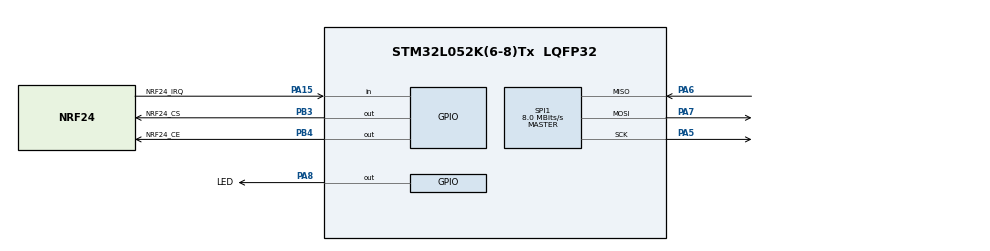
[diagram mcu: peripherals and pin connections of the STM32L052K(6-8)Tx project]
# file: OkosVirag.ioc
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ADC.EnableAnalogWatchDog=false
ADC.LowPowerAutoPowerOff=ENABLE
IWDG.Prescaler=IWDG_PRESCALER_256
Mcu.Family=STM32L0
Mcu.Name=STM32L052K(6-8)Tx
Mcu.Package=LQFP32
NVIC.RTC_IRQn=true\:0\:0\:false\:false\:true\:true
PA13.Mode=Serial_Wire
PA13.Signal=SYS_SWDIO
PA14.Mode=Serial_Wire
PA14.Signal=SYS_SWCLK
PA15.GPIO_Label=NRF24_IRQ
PA15.GPIO_PuPd=GPIO_PULLUP
PA15.Signal=GPIO_Input
PA5.Mode=Full_Duplex_Master
PA5.Signal=SPI1_SCK
PA6.Mode=Full_Duplex_Master
PA6.Signal=SPI1_MISO
PA7.Mode=Full_Duplex_Master
PA7.Signal=SPI1_MOSI
PA8.GPIO_Label=LED
PA8.Signal=GPIO_Output
PB3.GPIO_Label=NRF24_CS
PB3.GPIO_PuPd=GPIO_PULLUP
PB3.GPIO_Speed=GPIO_SPEED_FREQ_VERY_HIGH
PB3.Signal=GPIO_Output
PB4.GPIO_Label=NRF24_CE
PB4.GPIO_PuPd=GPIO_PULLUP
PB4.GPIO_Speed=GPIO_SPEED_FREQ_VERY_HIGH
PB4.Signal=GPIO_Output
ProjectManager.HeapSize=0x200
ProjectManager.StackSize=0x400
ProjectManager.TargetToolchain=SW4STM32
RCC.AHBFreq_Value=32000000
RCC.APB1Freq_Value=32000000
RCC.APB1TimFreq_Value=32000000
RCC.APB2Freq_Value=32000000
RCC.APB2TimFreq_Value=32000000
RCC.HCLKFreq_Value=32000000
RCC.HSI16_VALUE=16000000
RCC.HSI48_VALUE=48000000
RCC.HSI_VALUE=16000000
RCC.LSE_VALUE=32768
RCC.MSIClockRange=RCC_MSIRANGE_2
RCC.MSI_VALUE=262144
RCC.PLLMUL=RCC_PLLMUL_4
RCC.SYSCLKFreq_VALUE=32000000
RCC.SYSCLKSource=RCC_SYSCLKSOURCE_PLLCLK
RCC.VCOOutputFreq_Value=64000000
RTC.Format=RTC_FORMAT_BIN
RTC.WakeUpClock=RTC_WAKEUPCLOCK_CK_SPRE_16BITS
SPI1.BaudRatePrescaler=SPI_BAUDRATEPRESCALER_4
SPI1.CalculateBaudRate=8.0 MBits/s
SPI1.Direction=SPI_DIRECTION_2LINES
SPI1.Mode=SPI_MODE_MASTER
SPI1.VirtualType=VM_MASTER
VP_ADC_Vref_Input.Mode=IN-Vrefint
VP_IWDG_VS_IWDG.Mode=IWDG_Activate
VP_RTC_VS_RTC_Activate.Mode=RTC_Enabled
VP_RTC_VS_RTC_Calendar.Mode=RTC_Calendar
VP_RTC_VS_RTC_WakeUp_intern.Mode=WakeUp
board=OkosVirag

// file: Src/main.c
/**
  ******************************************************************************
  * File Name          : main.c
  * Description        : Main program body
  ******************************************************************************
  ** This notice applies to any and all portions of this file
  * that are not between comment pairs USER CODE BEGIN and
  * USER CODE END. Other portions of this file, whether
  * inserted by the user or by software development tools
  * are owned by their respective copyright owners.
  *
  * COPYRIGHT(c) 2018 STMicroelectronics
  *
  * Redistribution and use in source and binary forms, with or without modification,
  * are permitted provided that the following conditions are met:
  *   1. Redistributions of source code must retain the above copyright notice,
  *      this list of conditions and the following disclaimer.
  *   2. Redistributions in binary form must reproduce the above copyright notice,
  *      this list of conditions and the following disclaimer in the documentation
  *      and/or other materials provided with the distribution.
  *   3. Neither the name of STMicroelectronics nor the names of its contributors
  *      may be used to endorse or promote products derived from this software
  *      without specific prior written permission.
  *
  * THIS SOFTWARE IS PROVIDED BY THE COPYRIGHT HOLDERS AND CONTRIBUTORS "AS IS"
  * AND ANY EXPRESS OR IMPLIED WARRANTIES, INCLUDING, BUT NOT LIMITED TO, THE
  * IMPLIED WARRANTIES OF MERCHANTABILITY AND FITNESS FOR A PARTICULAR PURPOSE ARE
  * DISCLAIMED. IN NO EVENT SHALL THE COPYRIGHT HOLDER OR CONTRIBUTORS BE LIABLE
  * FOR ANY DIRECT, INDIRECT, INCIDENTAL, SPECIAL, EXEMPLARY, OR CONSEQUENTIAL
  * DAMAGES (INCLUDING, BUT NOT LIMITED TO, PROCUREMENT OF SUBSTITUTE GOODS OR
  * SERVICES; LOSS OF USE, DATA, OR PROFITS; OR BUSINESS INTERRUPTION) HOWEVER
  * CAUSED AND ON ANY THEORY OF LIABILITY, WHETHER IN CONTRACT, STRICT LIABILITY,
  * OR TORT (INCLUDING NEGLIGENCE OR OTHERWISE) ARISING IN ANY WAY OUT OF THE USE
  * OF THIS SOFTWARE, EVEN IF ADVISED OF THE POSSIBILITY OF SUCH DAMAGE.
  *
  ******************************************************************************
  */

#include "main.h"
#include "stm32l0xx_hal.h"
#include "adc.h"
#include "iwdg.h"
#include "rtc.h"
#include "spi.h"
#include "gpio.h"
#include "rcc.h"

/* USER CODE BEGIN Includes */
#include "Sleep.h"
/* USER CODE END Includes */

/* USER CODE BEGIN PV */
/* Private variables ---------------------------------------------------------*/

/* USER CODE END PV */

/* USER CODE BEGIN PFP */
/* Private function prototypes -----------------------------------------------*/

/* USER CODE END PFP */

int main(void)
{

  /* MCU Configuration----------------------------------------------------------*/

  /* Reset of all peripherals, Initializes the Flash interface and the Systick. */
  HAL_Init();

  /* Configure the system clock */
  SystemClock_Config();

  /* Initialize all configured peripherals */
  MX_GPIO_Init();
  MX_IWDG_Init();
  MX_RTC_Init();
//  HAL_RTC_MspInit(&hrtc);
  MX_ADC_Init();
  MX_SPI1_Init();

  /* Infinite loop */
  while (1)
  {

  /* USER CODE BEGIN 3 */
	  HAL_IWDG_Refresh(&hiwdg); //reload watchdog
	  HAL_GPIO_TogglePin(LED_GPIO_Port,LED_Pin);
	  HAL_Delay(30);
	  Sleep(10);

  }
  /* USER CODE END 3 */

}

void _Error_Handler(char * file, int line)
{
  while(1)
  {
  }
}

/************************ (C) COPYRIGHT STMicroelectronics *****END OF FILE****/
